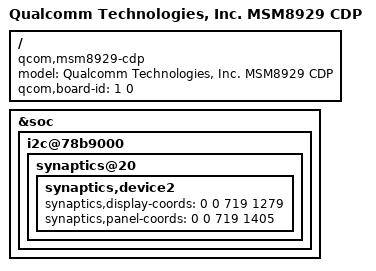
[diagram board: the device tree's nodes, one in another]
/*
 * Copyright (c) 2015, The Linux Foundation. All rights reserved.
 *
 * This program is free software; you can redistribute it and/or modify
 * it under the terms of the GNU General Public License version 2 and
 * only version 2 as published by the Free Software Foundation.
 *
 * This program is distributed in the hope that it will be useful,
 * but WITHOUT ANY WARRANTY; without even the implied warranty of
 * MERCHANTABILITY or FITNESS FOR A PARTICULAR PURPOSE.  See the
 * GNU General Public License for more details.
 */

/dts-v1/;

#include "msm8929.dtsi"
#include "msm8939-cdp.dtsi"

/ {
	model = "Qualcomm Technologies, Inc. MSM8929 CDP";
	compatible = "qcom,msm8929-cdp", "qcom,msm8929", "qcom,cdp";
	qcom,board-id = <1 0>;
};

&soc {
	i2c@78b9000 { /* BLSP1 QUP5 */
		synaptics@20 {
			/delete-node/ synaptics,device1;
			/delete-node/ synaptics,device3;
			synaptics,device2 {
				synaptics,display-coords = <0 0 719 1279>;
				synaptics,panel-coords = <0 0 719 1405>;
			};
		};
	};
};
